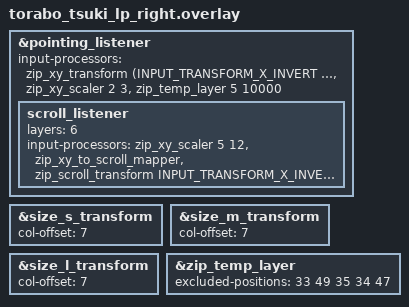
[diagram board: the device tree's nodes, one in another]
#include "torabo_tsuki_lp.dtsi"
#include <input/processors.dtsi>
#include <dt-bindings/zmk/input_transform.h>
#include <input/processors.dtsi>

&pointing_listener {
    input-processors = <&zip_xy_transform (INPUT_TRANSFORM_X_INVERT | INPUT_TRANSFORM_Y_INVERT)>
    ,<&zip_xy_scaler 2 3>
    ,<&zip_temp_layer 5 10000>;
    
    scroll_listener {
        layers = <6>;
        input-processors = <&zip_xy_scaler 5 12>
        , <&zip_xy_to_scroll_mapper>
        , <&zip_scroll_transform INPUT_TRANSFORM_X_INVERT>;
    };
};

&size_s_transform {
    col-offset = <7>;
};

&size_m_transform {
    col-offset = <7>;
};

&size_l_transform {
    col-offset = <7>;
};
&zip_temp_layer {
    excluded-positions = <
        33
        49
        35
        34
        47
    >;
};
